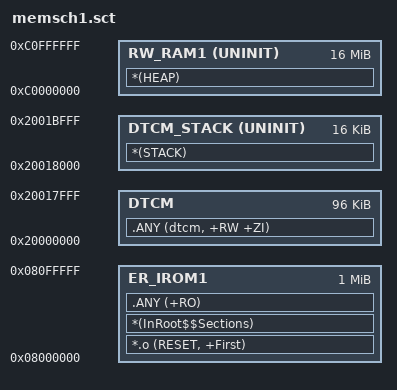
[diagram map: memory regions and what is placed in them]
; *************************************************************
; *** Scatter-Loading Description File generated by uVision ***
; *************************************************************

LR_IROM1 0x08000000 0x00100000  {    ; load region size_region
  ER_IROM1 0x08000000 0x00100000  {  ; load address = execution address
   *.o (RESET, +First)
   *(InRoot$$Sections)
   .ANY (+RO)
  }
  DTCM 0x20000000 0x00018000  {  ; DTCM
   .ANY (dtcm, +RW +ZI)
  }
  DTCM_STACK 0x20018000 UNINIT 0x00004000  {  ; DTCM
   *(STACK)
  }
  RW_RAM1 0xC0000000 UNINIT 0x01000000  { ; External SDRAM
   *(HEAP)
  }
}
